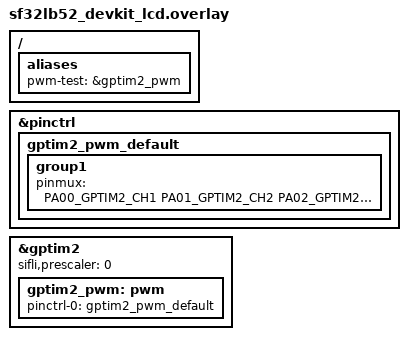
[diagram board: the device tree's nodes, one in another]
/*
 * SPDX-FileCopyrightText: Copyright The Zephyr Project Contributors
 * SPDX-License-Identifier: Apache-2.0
 */

/ {
	aliases {
		pwm-test = &gptim2_pwm;
	};
};

&pinctrl {
	gptim2_pwm_default: gptim2_pwm_default {
		group1 {
			pinmux = <
				PA00_GPTIM2_CH1
				PA01_GPTIM2_CH2
				PA02_GPTIM2_CH3
				PA03_GPTIM2_CH4
			>;
		};
	};
};

&gptim2 {
	status = "okay";
	sifli,prescaler = <0>;

	gptim2_pwm: pwm {
		status = "okay";
		pinctrl-0 = <&gptim2_pwm_default>;
		pinctrl-names = "default";
	};
};
